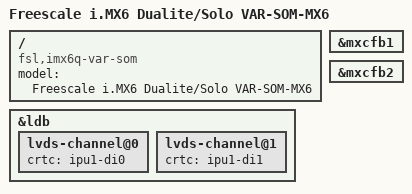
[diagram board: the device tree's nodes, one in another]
/*
 * Copyright (C) 2014 Variscite, Ltd. All Rights Reserved
 * Donio Ron: ron.d@variscite.com
 *
 * Copyright 2012 Freescale Semiconductor, Inc.
 * Copyright 2011 Linaro Ltd.
 *
 * The code contained herein is licensed under the GNU General Public
 * License. You may obtain a copy of the GNU General Public License
 * Version 2 or later at the following locations:
 *
 * http://www.opensource.org/licenses/gpl-license.html
 * http://www.gnu.org/copyleft/gpl.html
 */

/dts-v1/;

#define VAR_SOM_MX6

#include "imx6q.dtsi"
#include "imx6qdl-var-som.dtsi"

/ {
	model = "Freescale i.MX6 Dualite/Solo VAR-SOM-MX6";
	compatible = "fsl,imx6q-var-som", "fsl,imx6q";
};


&ldb {
	lvds-channel@0 {
		crtc = "ipu1-di0";
	};

	lvds-channel@1 {
		crtc = "ipu1-di1";
	};
};

&mxcfb1 {
	status = "okay";
};

&mxcfb2 {
	status = "okay";
};

